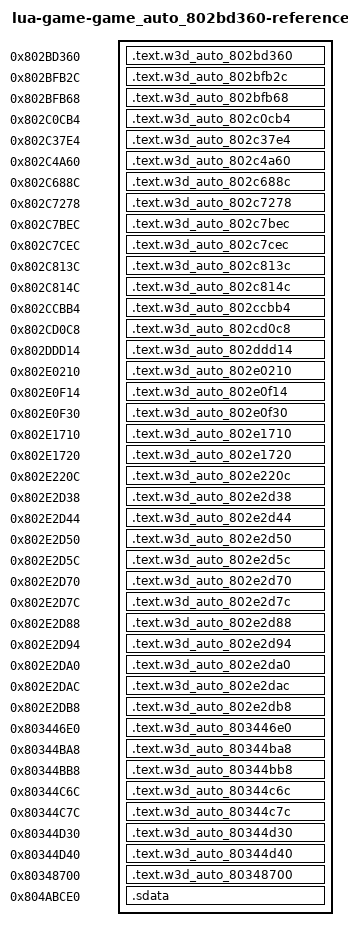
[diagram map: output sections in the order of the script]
/* Generated reference-only placements. All bodies are source-built. */
OUTPUT_FORMAT("elf32-powerpc")
OUTPUT_ARCH(powerpc)
ENTRY(w3d_auto_802bd360)
_SDA_BASE_ = 0x804b2540;
_SDA2_BASE_ = 0x804c2540;
fn_8015F5A0 = 0x8015f5a0;
fn_80162024 = 0x80162024;
fn_801FE1D8 = 0x801fe1d8;
fn_802BD354 = 0x802bd354;
fn_802BD4FC = 0x802bd4fc;
fn_802BD8CC = 0x802bd8cc;
fn_802BFC64 = 0x802bfc64;
fn_802C68BC = 0x802c68bc;
fn_802C76E8 = 0x802c76e8;
fn_802C7A98 = 0x802c7a98;
fn_802C7C1C = 0x802c7c1c;
fn_802C7D24 = 0x802c7d24;
fn_802C7E20 = 0x802c7e20;
fn_802CCBFC = 0x802ccbfc;
fn_802DDBD8 = 0x802ddbd8;
fn_802DDCC0 = 0x802ddcc0;
fn_802E0238 = 0x802e0238;
fn_802EF9C0 = 0x802ef9c0;
SECTIONS {
  .text.w3d_auto_802bd360 0x802bd360 : { *(.text.w3d_auto_802bd360) }
  .text.w3d_auto_802bfb2c 0x802bfb2c : { *(.text.w3d_auto_802bfb2c) }
  .text.w3d_auto_802bfb68 0x802bfb68 : { *(.text.w3d_auto_802bfb68) }
  .text.w3d_auto_802c0cb4 0x802c0cb4 : { *(.text.w3d_auto_802c0cb4) }
  .text.w3d_auto_802c37e4 0x802c37e4 : { *(.text.w3d_auto_802c37e4) }
  .text.w3d_auto_802c4a60 0x802c4a60 : { *(.text.w3d_auto_802c4a60) }
  .text.w3d_auto_802c688c 0x802c688c : { *(.text.w3d_auto_802c688c) }
  .text.w3d_auto_802c7278 0x802c7278 : { *(.text.w3d_auto_802c7278) }
  .text.w3d_auto_802c7bec 0x802c7bec : { *(.text.w3d_auto_802c7bec) }
  .text.w3d_auto_802c7cec 0x802c7cec : { *(.text.w3d_auto_802c7cec) }
  .text.w3d_auto_802c813c 0x802c813c : { *(.text.w3d_auto_802c813c) }
  .text.w3d_auto_802c814c 0x802c814c : { *(.text.w3d_auto_802c814c) }
  .text.w3d_auto_802ccbb4 0x802ccbb4 : { *(.text.w3d_auto_802ccbb4) }
  .text.w3d_auto_802cd0c8 0x802cd0c8 : { *(.text.w3d_auto_802cd0c8) }
  .text.w3d_auto_802ddd14 0x802ddd14 : { *(.text.w3d_auto_802ddd14) }
  .text.w3d_auto_802e0210 0x802e0210 : { *(.text.w3d_auto_802e0210) }
  .text.w3d_auto_802e0f14 0x802e0f14 : { *(.text.w3d_auto_802e0f14) }
  .text.w3d_auto_802e0f30 0x802e0f30 : { *(.text.w3d_auto_802e0f30) }
  .text.w3d_auto_802e1710 0x802e1710 : { *(.text.w3d_auto_802e1710) }
  .text.w3d_auto_802e1720 0x802e1720 : { *(.text.w3d_auto_802e1720) }
  .text.w3d_auto_802e220c 0x802e220c : { *(.text.w3d_auto_802e220c) }
  .text.w3d_auto_802e2d38 0x802e2d38 : { *(.text.w3d_auto_802e2d38) }
  .text.w3d_auto_802e2d44 0x802e2d44 : { *(.text.w3d_auto_802e2d44) }
  .text.w3d_auto_802e2d50 0x802e2d50 : { *(.text.w3d_auto_802e2d50) }
  .text.w3d_auto_802e2d5c 0x802e2d5c : { *(.text.w3d_auto_802e2d5c) }
  .text.w3d_auto_802e2d70 0x802e2d70 : { *(.text.w3d_auto_802e2d70) }
  .text.w3d_auto_802e2d7c 0x802e2d7c : { *(.text.w3d_auto_802e2d7c) }
  .text.w3d_auto_802e2d88 0x802e2d88 : { *(.text.w3d_auto_802e2d88) }
  .text.w3d_auto_802e2d94 0x802e2d94 : { *(.text.w3d_auto_802e2d94) }
  .text.w3d_auto_802e2da0 0x802e2da0 : { *(.text.w3d_auto_802e2da0) }
  .text.w3d_auto_802e2dac 0x802e2dac : { *(.text.w3d_auto_802e2dac) }
  .text.w3d_auto_802e2db8 0x802e2db8 : { *(.text.w3d_auto_802e2db8) }
  .text.w3d_auto_803446e0 0x803446e0 : { *(.text.w3d_auto_803446e0) }
  .text.w3d_auto_80344ba8 0x80344ba8 : { *(.text.w3d_auto_80344ba8) }
  .text.w3d_auto_80344bb8 0x80344bb8 : { *(.text.w3d_auto_80344bb8) }
  .text.w3d_auto_80344c6c 0x80344c6c : { *(.text.w3d_auto_80344c6c) }
  .text.w3d_auto_80344c7c 0x80344c7c : { *(.text.w3d_auto_80344c7c) }
  .text.w3d_auto_80344d30 0x80344d30 : { *(.text.w3d_auto_80344d30) }
  .text.w3d_auto_80344d40 0x80344d40 : { *(.text.w3d_auto_80344d40) }
  .text.w3d_auto_80348700 0x80348700 : { *(.text.w3d_auto_80348700) }
  .sdata 0x804abce0 (NOLOAD) : {
    . = 0x0; lbl_804ABCE0 = .;
    . = 0x4; lbl_804ABCE4 = .;
    . = 0x5390; lbl_804B1070 = .;
    . = 0x5398; lbl_804B1078 = .;
    . = 0x53a0; lbl_804B1080 = .;
    . = 0x53a8; lbl_804B1088 = .;
    . = 0x53b0; lbl_804B1090 = .;
    . = 0x53b8; lbl_804B1098 = .;
    . += 1; }
  /DISCARD/ : { *(.text*) *(.rodata*) *(.data*) *(.bss*) *(.sdata*) *(.sbss*) *(.comment) }
}
